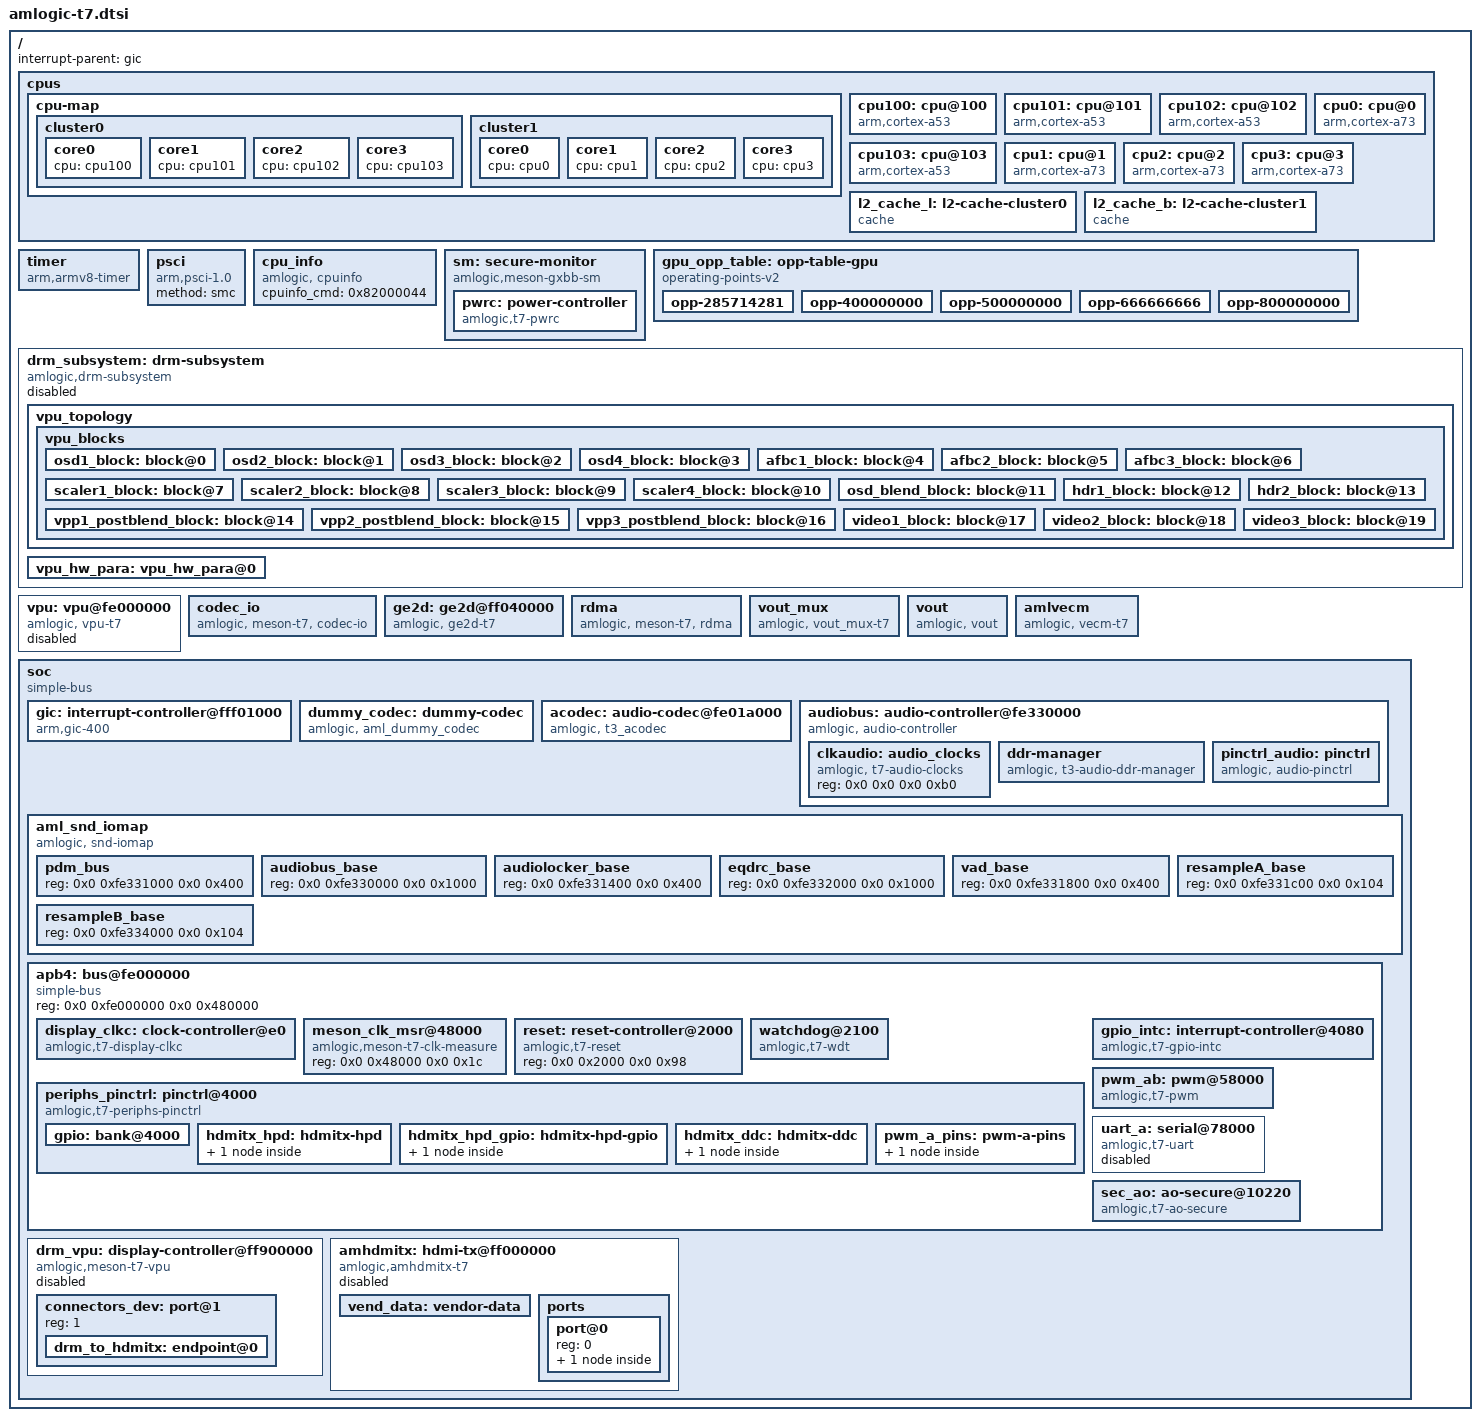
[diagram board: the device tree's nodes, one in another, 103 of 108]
// SPDX-License-Identifier: (GPL-2.0+ OR MIT)
/*
 * Copyright (c) 2019 Amlogic, Inc. All rights reserved.
 */

#include <dt-bindings/interrupt-controller/arm-gic.h>
#include <dt-bindings/clock/amlogic,t7-audio-clk.h>
#include <dt-bindings/clock/amlogic,t7-display-clkc.h>
#include <dt-bindings/display/meson-drm-ids.h>
#include <dt-bindings/power/amlogic,t7-pwrc.h>
#include "amlogic-t7-reset.h"

/ {
	interrupt-parent = <&gic>;
	#address-cells = <2>;
	#size-cells = <2>;

	cpus {
		#address-cells = <0x2>;
		#size-cells = <0x0>;

		cpu-map {
			cluster0 {
				core0 {
					cpu = <&cpu100>;
				};
				core1 {
					cpu = <&cpu101>;
				};
				core2 {
					cpu = <&cpu102>;
				};
				core3 {
					cpu = <&cpu103>;
				};
			};

			cluster1 {
				core0 {
					cpu = <&cpu0>;
				};
				core1 {
					cpu = <&cpu1>;
				};
				core2 {
					cpu = <&cpu2>;
				};
				core3 {
					cpu = <&cpu3>;
				};
			};
		};

		cpu100: cpu@100 {
			device_type = "cpu";
			compatible = "arm,cortex-a53";
			reg = <0x0 0x100>;
			enable-method = "psci";
			d-cache-line-size = <32>;
			d-cache-size = <0x8000>;
			d-cache-sets = <32>;
			i-cache-line-size = <32>;
			i-cache-size = <0x8000>;
			i-cache-sets = <32>;
			next-level-cache = <&l2_cache_l>;
		};

		cpu101: cpu@101 {
			device_type = "cpu";
			compatible = "arm,cortex-a53";
			reg = <0x0 0x101>;
			enable-method = "psci";
			d-cache-line-size = <32>;
			d-cache-size = <0x8000>;
			d-cache-sets = <32>;
			i-cache-line-size = <32>;
			i-cache-size = <0x8000>;
			i-cache-sets = <32>;
			next-level-cache = <&l2_cache_l>;
		};

		cpu102: cpu@102 {
			device_type = "cpu";
			compatible = "arm,cortex-a53";
			reg = <0x0 0x102>;
			enable-method = "psci";
			d-cache-line-size = <32>;
			d-cache-size = <0x8000>;
			d-cache-sets = <32>;
			i-cache-line-size = <32>;
			i-cache-size = <0x8000>;
			i-cache-sets = <32>;
			next-level-cache = <&l2_cache_l>;
		};

		cpu103: cpu@103 {
			device_type = "cpu";
			compatible = "arm,cortex-a53";
			reg = <0x0 0x103>;
			enable-method = "psci";
			d-cache-line-size = <32>;
			d-cache-size = <0x8000>;
			d-cache-sets = <32>;
			i-cache-line-size = <32>;
			i-cache-size = <0x8000>;
			i-cache-sets = <32>;
			next-level-cache = <&l2_cache_l>;
		};

		cpu0: cpu@0 {
			device_type = "cpu";
			compatible = "arm,cortex-a73";
			reg = <0x0 0x0>;
			enable-method = "psci";
			d-cache-line-size = <64>;
			d-cache-size = <0x10000>;
			d-cache-sets = <64>;
			i-cache-line-size = <64>;
			i-cache-size = <0x10000>;
			i-cache-sets = <64>;
			next-level-cache = <&l2_cache_b>;
		};

		cpu1: cpu@1 {
			device_type = "cpu";
			compatible = "arm,cortex-a73";
			reg = <0x0 0x1>;
			enable-method = "psci";
			d-cache-line-size = <64>;
			d-cache-size = <0x10000>;
			d-cache-sets = <64>;
			i-cache-line-size = <64>;
			i-cache-size = <0x10000>;
			i-cache-sets = <64>;
			next-level-cache = <&l2_cache_b>;
		};

		cpu2: cpu@2 {
			device_type = "cpu";
			compatible = "arm,cortex-a73";
			reg = <0x0 0x2>;
			enable-method = "psci";
			d-cache-line-size = <64>;
			d-cache-size = <0x10000>;
			d-cache-sets = <64>;
			i-cache-line-size = <64>;
			i-cache-size = <0x10000>;
			i-cache-sets = <64>;
			next-level-cache = <&l2_cache_b>;
		};

		cpu3: cpu@3 {
			device_type = "cpu";
			compatible = "arm,cortex-a73";
			reg = <0x0 0x3>;
			enable-method = "psci";
			d-cache-line-size = <64>;
			d-cache-size = <0x10000>;
			d-cache-sets = <64>;
			i-cache-line-size = <64>;
			i-cache-size = <0x10000>;
			i-cache-sets = <64>;
			next-level-cache = <&l2_cache_b>;
		};

		l2_cache_l: l2-cache-cluster0 {
			compatible = "cache";
			cache-level = <2>;
			cache-unified;
			cache-size = <0x40000>;  /* L2. 256 KB */
			cache-line-size = <64>;
			cache-sets = <512>;
		};

		l2_cache_b: l2-cache-cluster1 {
			compatible = "cache";
			cache-level = <2>;
			cache-unified;
			cache-size = <0x100000>; /* L2. 1 Mb */
			cache-line-size = <64>;
			cache-sets = <512>;
		};
	};

	timer {
		compatible = "arm,armv8-timer";
		interrupts = <GIC_PPI 13 (GIC_CPU_MASK_SIMPLE(8) | IRQ_TYPE_LEVEL_LOW)>,
			     <GIC_PPI 14 (GIC_CPU_MASK_SIMPLE(8) | IRQ_TYPE_LEVEL_LOW)>,
			     <GIC_PPI 11 (GIC_CPU_MASK_SIMPLE(8) | IRQ_TYPE_LEVEL_LOW)>,
			     <GIC_PPI 10 (GIC_CPU_MASK_SIMPLE(8) | IRQ_TYPE_LEVEL_LOW)>;
	};

	psci {
		compatible = "arm,psci-1.0";
		method = "smc";
	};

	cpu_info {
		compatible = "amlogic, cpuinfo";
		status = "okay";
		cpuinfo_cmd = <0x82000044>;
	};

	sm: secure-monitor {
		compatible = "amlogic,meson-gxbb-sm";

		pwrc: power-controller {
			compatible = "amlogic,t7-pwrc";
			#power-domain-cells = <1>;
		};
	};

	gpu_opp_table: opp-table-gpu {
		compatible = "operating-points-v2";

		opp-285714281 {
			opp-hz = /bits/ 64 <285714281>;
			opp-microvolt = <1150000>;
		};

		opp-400000000 {
			opp-hz = /bits/ 64 <400000000>;
			opp-microvolt = <1150000>;
		};

		opp-500000000 {
			opp-hz = /bits/ 64 <500000000>;
			opp-microvolt = <1150000>;
		};

		opp-666666666 {
			opp-hz = /bits/ 64 <666666666>;
			opp-microvolt = <1150000>;
		};

		opp-800000000 {
			opp-hz = /bits/ 64 <800000000>;
			opp-microvolt = <1150000>;
		};
	};

	drm_subsystem: drm-subsystem {
		compatible = "amlogic,drm-subsystem", "amlogic, drm-subsystem";
		status = "disabled";

		vpu_dma_mask = <1>;
		ports = <&connectors_dev>;
		fbdev_sizes = <1920 1080 1920 2160 32>;
		osd_ver = /bits/ 8 <OSD_V7>;
		vfm_mode = <1>;
		crtc_masks = <7 7 1>;
		crtcmask_of_osd = <0 0 1 2>;
		crtcmask_of_video = <0 1 2>;

		vpu_topology: vpu_topology {
			vpu_blocks {
				osd1_block: block@0 {
					id = /bits/ 8 <OSD1_BLOCK>;
					index = /bits/ 8 <0>;
					type = /bits/ 8 <0>;
					block_name = "osd1_block";
					num_in_links = /bits/ 8 <0x0>;
					num_out_links = /bits/ 8 <0x1>;
					out_links = <0 &afbc1_block>;
				};

				osd2_block: block@1 {
					id = /bits/ 8 <OSD2_BLOCK>;
					index = /bits/ 8 <1>;
					type = /bits/ 8 <0>;
					block_name = "osd2_block";
					num_in_links = /bits/ 8 <0x0>;
					num_out_links = /bits/ 8 <0x1>;
					out_links = <1 &afbc1_block>;
				};

				osd3_block: block@2 {
					id = /bits/ 8 <OSD3_BLOCK>;
					index = /bits/ 8 <2>;
					type = /bits/ 8 <0>;
					block_name = "osd3_block";
					num_in_links = /bits/ 8 <0x0>;
					num_out_links = /bits/ 8 <0x1>;
					out_links = <0 &afbc2_block>;
				};

				osd4_block: block@3 {
					id = /bits/ 8 <OSD4_BLOCK>;
					index = /bits/ 8 <3>;
					type = /bits/ 8 <0>;
					block_name = "osd4_block";
					num_in_links = /bits/ 8 <0x0>;
					num_out_links = /bits/ 8 <0x1>;
					out_links = <0 &afbc3_block>;
				};

				afbc1_block: block@4 {
					id = /bits/ 8 <AFBC1_BLOCK>;
					index = /bits/ 8 <0>;
					type = /bits/ 8 <1>;
					block_name = "afbc1_block";
					num_in_links = /bits/ 8 <0x2>;
					in_links = <0 &osd1_block>,
						   <0 &osd2_block>;
					num_out_links = /bits/ 8 <0x2>;
					out_links = <0 &osd_blend_block>,
						    <0 &scaler2_block>;
				};

				afbc2_block: block@5 {
					id = /bits/ 8 <AFBC2_BLOCK>;
					index = /bits/ 8 <1>;
					type = /bits/ 8 <1>;
					block_name = "afbc2_block";
					num_in_links = /bits/ 8 <0x1>;
					in_links = <0 &osd3_block>;
					num_out_links = /bits/ 8 <0x1>;
					out_links = <0 &scaler3_block>;
				};

				afbc3_block: block@6 {
					id = /bits/ 8 <AFBC3_BLOCK>;
					index = /bits/ 8 <2>;
					type = /bits/ 8 <1>;
					block_name = "afbc3_block";
					num_in_links = /bits/ 8 <0x1>;
					in_links = <0 &osd4_block>;
					num_out_links = /bits/ 8 <0x1>;
					out_links = <0 &scaler4_block>;
				};

				scaler1_block: block@7 {
					id = /bits/ 8 <SCALER1_BLOCK>;
					index = /bits/ 8 <0>;
					type = /bits/ 8 <2>;
					block_name = "scaler1_block";
					num_in_links = /bits/ 8 <0x1>;
					in_links = <0 &hdr1_block>;
					num_out_links = /bits/ 8 <0x1>;
					out_links = <0 &vpp1_postblend_block>;
				};

				scaler2_block: block@8 {
					id = /bits/ 8 <SCALER2_BLOCK>;
					index = /bits/ 8 <1>;
					type = /bits/ 8 <2>;
					block_name = "scaler2_block";
					num_in_links = /bits/ 8 <0x1>;
					in_links = <1 &afbc1_block>;
					num_out_links = /bits/ 8 <0x1>;
					out_links = <1 &osd_blend_block>;
				};

				scaler3_block: block@9 {
					id = /bits/ 8 <SCALER3_BLOCK>;
					index = /bits/ 8 <2>;
					type = /bits/ 8 <2>;
					block_name = "scaler3_block";
					num_in_links = /bits/ 8 <0x1>;
					in_links = <0 &afbc2_block>;
					num_out_links = /bits/ 8 <0x2>;
					out_links = <2 &osd_blend_block>,
						    <0 &hdr2_block>;
				};

				scaler4_block: block@10 {
					id = /bits/ 8 <SCALER4_BLOCK>;
					index = /bits/ 8 <3>;
					type = /bits/ 8 <2>;
					block_name = "scaler4_block";
					num_in_links = /bits/ 8 <0x1>;
					in_links = <0 &afbc3_block>;
					num_out_links = /bits/ 8 <0x2>;
					out_links = <3 &osd_blend_block>,
						    <0 &vpp3_postblend_block>;
				};

				osd_blend_block: block@11 {
					id = /bits/ 8 <OSD_BLEND_BLOCK>;
					block_name = "osd_blend_block";
					type = /bits/ 8 <3>;
					num_in_links = /bits/ 8 <0x4>;
					in_links = <0 &afbc1_block>,
						   <0 &scaler2_block>,
						   <0 &scaler3_block>,
						   <0 &scaler4_block>;
					num_out_links = /bits/ 8 <0x1>;
					out_links = <0 &hdr1_block>;
				};

				hdr1_block: block@12 {
					id = /bits/ 8 <HDR1_BLOCK>;
					index = /bits/ 8 <0>;
					block_name = "hdr1_block";
					type = /bits/ 8 <4>;
					num_in_links = /bits/ 8 <0x1>;
					in_links = <0 &osd_blend_block>;
					num_out_links = /bits/ 8 <0x1>;
					out_links = <0 &scaler1_block>;
				};

				hdr2_block: block@13 {
					id = /bits/ 8 <HDR2_BLOCK>;
					index = /bits/ 8 <1>;
					block_name = "hdr2_block";
					type = /bits/ 8 <4>;
					num_in_links = /bits/ 8 <0x1>;
					in_links = <1 &osd_blend_block>;
					num_out_links = /bits/ 8 <0x1>;
					out_links = <0 &vpp2_postblend_block>;
				};

				vpp1_postblend_block: block@14 {
					id = /bits/ 8 <VPP1_POSTBLEND_BLOCK>;
					index = /bits/ 8 <0>;
					block_name = "vpp1_postblend_block";
					type = /bits/ 8 <6>;
					num_in_links = /bits/ 8 <0x1>;
					in_links = <0 &scaler1_block>;
					num_out_links = <0x0>;
				};

				vpp2_postblend_block: block@15 {
					id = /bits/ 8 <VPP2_POSTBLEND_BLOCK>;
					index = /bits/ 8 <1>;
					block_name = "vpp2_postblend_block";
					type = /bits/ 8 <6>;
					num_in_links = /bits/ 8 <0x1>;
					in_links = <1 &hdr2_block>;
					num_out_links = <0x0>;
				};

				vpp3_postblend_block: block@16 {
					id = /bits/ 8 <VPP3_POSTBLEND_BLOCK>;
					index = /bits/ 8 <2>;
					block_name = "vpp3_postblend_block";
					type = /bits/ 8 <6>;
					num_in_links = /bits/ 8 <0x1>;
					in_links = <0 &scaler4_block>;
					num_out_links = <0x0>;
				};

				video1_block: block@17 {
					id = /bits/ 8 <VIDEO1_BLOCK>;
					index = /bits/ 8 <0>;
					type = /bits/ 8 <7>;
					block_name = "video1_block";
					num_in_links = /bits/ 8 <0x0>;
					num_out_links = /bits/ 8 <0x0>;
				};

				video2_block: block@18 {
					id = /bits/ 8 <VIDEO2_BLOCK>;
					index = /bits/ 8 <1>;
					type = /bits/ 8 <7>;
					block_name = "video2_block";
					num_in_links = /bits/ 8 <0x0>;
					num_out_links = /bits/ 8 <0x0>;
				};

				video3_block: block@19 {
					id = /bits/ 8 <VIDEO3_BLOCK>;
					index = /bits/ 8 <2>;
					type = /bits/ 8 <7>;
					block_name = "video3_block";
					num_in_links = /bits/ 8 <0x0>;
					num_out_links = /bits/ 8 <0x0>;
				};
			};
		};

		vpu_hw_para: vpu_hw_para@0 {
			osd_ver = /bits/ 8 <OSD_V7>;
			afbc_type = /bits/ 8 <0x2>;
			has_deband = /bits/ 8 <0x1>;
			has_lut = /bits/ 8 <0x1>;
			has_rdma = /bits/ 8 <0x1>;
			osd_fifo_len = /bits/ 8 <64>;
			vpp_fifo_len = /bits/ 32 <0xfff>;
		};
	};

	vpu: vpu@fe000000 {
		compatible = "amlogic, vpu-t7";
		status = "disabled";
		reg = <0x0 0xfe000000 0x0 0x100>,
		      <0x0 0xfe00c000 0x0 0x70>,
		      <0x0 0xff000000 0x0 0xf000>;
		clocks = <&display_clkc CLKID_T7_DISPLAY_VAPB>,
			 <&clkc_periphs CLKID_SYS_VPU_INTR>,
			 <&display_clkc CLKID_T7_DISPLAY_VPU_0>,
			 <&display_clkc CLKID_T7_DISPLAY_VPU_1>,
			 <&display_clkc CLKID_T7_DISPLAY_VPU>;
		clock-names = "vapb_clk", "vpu_intr_gate",
			      "vpu_clk0", "vpu_clk1", "vpu_clk";
		clk_level = <8>;
	};

	codec_io: codec_io {
		compatible = "amlogic, meson-t7, codec-io";
		status = "okay";
		#address-cells = <2>;
		#size-cells = <2>;
		ranges;
		/* Positional resources used by the vendor codec_io bus enum. */
		reg = <0x0 0xfe002000 0x0 0x2000>,
		      <0x0 0xfe320000 0x0 0x10000>,
		      <0x0 0x0 0x0 0x0>,
		      <0x0 0x0 0x0 0x0>,
		      <0x0 0xff000000 0x0 0x40000>,
		      <0x0 0xfe036000 0x0 0x2000>,
		      <0x0 0x0 0x0 0x0>;
		reg-names = "cbus",
			    "dosbus",
			    "hiubus",
			    "aobus",
			    "vcbus",
			    "dmcbus",
			    "efusebus";
	};

	ge2d: ge2d@ff040000 {
		compatible = "amlogic, ge2d-t7";
		status = "okay";
		interrupts = <GIC_SPI 217 IRQ_TYPE_EDGE_RISING>;
		interrupt-names = "ge2d";
		clocks = <&display_clkc CLKID_T7_DISPLAY_VAPB>,
			 <&clkc_periphs CLKID_SYS_G2D>,
			 <&display_clkc CLKID_T7_DISPLAY_GE2D>;
		clock-names = "clk_vapb_0",
			      "clk_ge2d",
			      "clk_ge2d_gate";
		reg = <0x0 0xff040000 0x0 0x100>;
		power-domains = <&pwrc PWRC_T7_GE2D_ID>;
	};

	rdma {
		compatible = "amlogic, meson-t7, rdma";
		status = "okay";
		interrupts = <GIC_SPI 215 IRQ_TYPE_EDGE_RISING>;
		interrupt-names = "rdma";
		reset-names = "rdma";
		resets = <&reset RESET_RDMA>;
		rdma_table_page_count = <16>;
	};

	vout_mux: vout_mux {
		compatible = "amlogic, vout_mux-t7";
		status = "okay";
	};

	vout: vout {
		compatible = "amlogic, vout";
		status = "okay";
	};

	amlvecm: amlvecm {
		compatible = "amlogic, vecm-t7", "amlogic, vecm";
		dev_name = "aml_vecm";
		clocks = <&display_clkc CLKID_T7_DISPLAY_VID_LOCK>;
		clock-names = "cts_vid_lock_clk";
	};

	soc {
		compatible = "simple-bus";
		#address-cells = <2>;
		#size-cells = <2>;
		ranges;

		gic: interrupt-controller@fff01000 {
			compatible = "arm,gic-400";
			#interrupt-cells = <3>;
			#address-cells = <0>;
			interrupt-controller;
			reg = <0x0 0xfff01000 0 0x1000>,
			      <0x0 0xfff02000 0 0x2000>,
			      <0x0 0xfff04000 0 0x2000>,
			      <0x0 0xfff06000 0 0x2000>;
			interrupts = <GIC_PPI 9 (GIC_CPU_MASK_SIMPLE(8) | IRQ_TYPE_LEVEL_HIGH)>;
		};

		dummy_codec: dummy-codec {
			compatible = "amlogic, aml_dummy_codec";
			#sound-dai-cells = <0>;
			status = "okay";
		};

		acodec: audio-codec@fe01a000 {
			compatible = "amlogic, t3_acodec";
			reg = <0x0 0xfe01a000 0x0 0x1c>;
			clocks = <&clkc_periphs CLKID_SYS_ACODEC>;
			clock-names = "acodec_clk";
			resets = <&reset RESET_ACODEC>;
			reset-names = "acodec";
			#sound-dai-cells = <0>;
			tdmout_index = <1>;
			tdmin_index = <1>;
			dat0_ch_sel = <1>;
			lane_offset = <8>;
			amlogic,skip-reset-startup;
			status = "okay";
		};

		audiobus: audio-controller@fe330000 {
			compatible = "amlogic, audio-controller", "simple-bus";
			reg = <0x0 0xfe330000 0x0 0x3000>;
			clocks = <&clkc_periphs CLKID_SYS_AUDIO>;
			clock-names = "pclk";
			power-domains = <&pwrc PWRC_T7_AUDIO_ID>;
			#address-cells = <2>;
			#size-cells = <2>;
			ranges = <0x0 0x0 0x0 0xfe330000 0x0 0x3000>;
			chip_id = <0x36>;
			status = "okay";

			clkaudio: audio_clocks {
				compatible = "amlogic, t7-audio-clocks";
				#clock-cells = <1>;
				reg = <0x0 0x0 0x0 0xb0>;
				status = "okay";
			};

			ddr-manager {
				compatible = "amlogic, t3-audio-ddr-manager";
				interrupts = <GIC_SPI 32 IRQ_TYPE_EDGE_RISING>,
					     <GIC_SPI 33 IRQ_TYPE_EDGE_RISING>,
					     <GIC_SPI 34 IRQ_TYPE_EDGE_RISING>,
					     <GIC_SPI 45 IRQ_TYPE_EDGE_RISING>,
					     <GIC_SPI 40 IRQ_TYPE_EDGE_RISING>,
					     <GIC_SPI 36 IRQ_TYPE_EDGE_RISING>,
					     <GIC_SPI 37 IRQ_TYPE_EDGE_RISING>,
					     <GIC_SPI 38 IRQ_TYPE_EDGE_RISING>,
					     <GIC_SPI 46 IRQ_TYPE_EDGE_RISING>,
					     <GIC_SPI 47 IRQ_TYPE_EDGE_RISING>;
				interrupt-names = "toddr_a", "toddr_b", "toddr_c",
						  "toddr_d", "toddr_e",
						  "frddr_a", "frddr_b", "frddr_c",
						  "frddr_d", "frddr_e";
				status = "okay";
			};

			pinctrl_audio: pinctrl {
				compatible = "amlogic, audio-pinctrl";
				status = "okay";
			};
		};

		aml_snd_iomap {
			compatible = "amlogic, snd-iomap";
			status = "okay";
			#address-cells = <2>;
			#size-cells = <2>;
			ranges;

			pdm_bus {
				reg = <0x0 0xfe331000 0x0 0x400>;
			};

			audiobus_base {
				reg = <0x0 0xfe330000 0x0 0x1000>;
			};

			audiolocker_base {
				reg = <0x0 0xfe331400 0x0 0x400>;
			};

			eqdrc_base {
				reg = <0x0 0xfe332000 0x0 0x1000>;
			};

			vad_base {
				reg = <0x0 0xfe331800 0x0 0x400>;
			};

			resampleA_base {
				reg = <0x0 0xfe331c00 0x0 0x104>;
			};

			resampleB_base {
				reg = <0x0 0xfe334000 0x0 0x104>;
			};
		};

		apb4: bus@fe000000 {
			compatible = "simple-bus";
			reg = <0x0 0xfe000000 0x0 0x480000>;
			#address-cells = <2>;
			#size-cells = <2>;
			ranges = <0x0 0x0 0x0 0xfe000000 0x0 0x480000>;

			display_clkc: clock-controller@e0 {
				compatible = "amlogic,t7-display-clkc";
				reg = <0x0 0x00e0 0x0 0x44>,
				      <0x0 0x0140 0x0 0x10>;
				#clock-cells = <1>;
				clocks = <&xtal>,
					 <&fdiv2p5>,
					 <&fdiv3>,
					 <&fdiv4>,
					 <&fdiv5>,
					 <&fdiv7>;
				clock-names = "xtal",
					      "fdiv2p5",
					      "fdiv3",
					      "fdiv4",
					      "fdiv5",
					      "fdiv7";
			};

			meson_clk_msr@48000 {
				compatible = "amlogic,meson-t7-clk-measure";
				reg = <0x0 0x48000 0x0 0x1c>;
			};

			reset: reset-controller@2000 {
				compatible = "amlogic,t7-reset";
				reg = <0x0 0x2000 0x0 0x98>;
				#reset-cells = <1>;
			};

			watchdog@2100 {
				compatible = "amlogic,t7-wdt";
				reg = <0x0 0x2100 0x0 0x10>;
				clocks = <&xtal>;
			};

			periphs_pinctrl: pinctrl@4000 {
				compatible = "amlogic,t7-periphs-pinctrl";
				#address-cells = <2>;
				#size-cells = <2>;
				ranges;

				gpio: bank@4000 {
					reg = <0x0 0x4000 0x0 0x0064>,
					      <0x0 0x40c0 0x0 0x0220>;
					reg-names = "mux", "gpio";
					gpio-controller;
					#gpio-cells = <2>;
					gpio-ranges = <&periphs_pinctrl 0 0 157>;
				};

				hdmitx_hpd: hdmitx-hpd {
					mux {
						groups = "hdmitx_hpd_in";
						function = "hdmitx";
						bias-disable;
					};
				};

				hdmitx_hpd_gpio: hdmitx-hpd-gpio {
					mux {
						groups = "GPIOW_15";
						function = "gpio_periphs";
						bias-disable;
					};
				};

				hdmitx_ddc: hdmitx-ddc {
					mux {
						groups = "hdmitx_sda_w13", "hdmitx_sck_w14";
						function = "hdmitx";
						bias-disable;
						drive-strength-microamp = <3000>;
					};
				};

				pwm_a_pins: pwm-a-pins {
					mux {
						groups = "pwm_a";
						function = "pwm_a";
						bias-disable;
					};
				};
			};

			gpio_intc: interrupt-controller@4080 {
				compatible = "amlogic,t7-gpio-intc",
					     "amlogic,meson-gpio-intc";
				reg = <0x0 0x4080 0x0 0x20>;
				interrupt-controller;
				#interrupt-cells = <2>;
				amlogic,channel-interrupts =
					<10 11 12 13 14 15 16 17 18 19 20 21>;
			};

			pwm_ab: pwm@58000 {
				compatible = "amlogic,t7-pwm", "amlogic,meson-s4-pwm";
				reg = <0x0 0x58000 0x0 0x24>;
				clocks = <&clkc_periphs CLKID_PWM_A>,
					 <&clkc_periphs CLKID_PWM_B>;
				#pwm-cells = <3>;
				status = "okay";
			};

			uart_a: serial@78000 {
				compatible = "amlogic,t7-uart", "amlogic,meson-s4-uart";
				reg = <0x0 0x78000 0x0 0x18>;
				interrupts = <GIC_SPI 168 IRQ_TYPE_EDGE_RISING>;
				status = "disabled";
			};

			sec_ao: ao-secure@10220 {
				compatible = "amlogic,t7-ao-secure",
					     "amlogic,meson-gx-ao-secure",
					     "syscon";
				reg = <0x0 0x10220 0x0 0x140>;
				amlogic,has-chip-id;
			};
		};

		drm_vpu: display-controller@ff900000 {
			compatible = "amlogic,meson-t7-vpu", "amlogic, meson-t7-vpu";
			status = "disabled";
			osd_ver = /bits/ 8 <OSD_V7>;
			osd_axi_sel = <0>;
			power-domains = <&pwrc PWRC_T7_VPU_HDMI_ID>;
			clocks = <&display_clkc CLKID_T7_DISPLAY_VAPB>,
				 <&clkc_periphs CLKID_SYS_VPU_INTR>,
				 <&display_clkc CLKID_T7_DISPLAY_VPU_0>,
				 <&display_clkc CLKID_T7_DISPLAY_VPU_1>,
				 <&display_clkc CLKID_T7_DISPLAY_VPU>;
			clock-names = "vapb_clk", "vpu_intr_gate",
				      "vpu_clk0", "vpu_clk1", "vpu_clk";
			resets = <&reset RESET_VIU>,
				 <&reset RESET_VENC>;
			reset-names = "viu", "venc";
			reg = <0x0 0xff900000 0x0 0x40000>,
			      <0x0 0xff63c000 0x0 0x2000>,
			      <0x0 0xff638000 0x0 0x2000>;
			reg-names = "base", "hhi", "dmc";
			interrupts = <GIC_SPI 197 IRQ_TYPE_EDGE_RISING>,
				     <GIC_SPI 194 IRQ_TYPE_EDGE_RISING>,
				     <GIC_SPI 82 IRQ_TYPE_EDGE_RISING>;
			interrupt-names = "drm-viu-vsync", "drm-viu2-vsync",
					  "drm-viu3-vsync";
			dma-coherent;

			#address-cells = <1>;
			#size-cells = <0>;

			connectors_dev: port@1 {
				reg = <1>;
				#address-cells = <1>;
				#size-cells = <0>;

				drm_to_hdmitx: endpoint@0 {
					reg = <0>;
					remote-endpoint = <&hdmitx_to_drm>;
				};
			};
		};

		amhdmitx: hdmi-tx@ff000000 {
			compatible = "amlogic,amhdmitx-t7", "amlogic, amhdmitx-t7";
			dev_name = "amhdmitx";
			status = "disabled";
			power-domains = <&pwrc PWRC_T7_VI_CLK2_ID>;
			clocks = <&clkc_periphs CLKID_SYS_HDMITX_APB>,
				 <&display_clkc CLKID_T7_DISPLAY_HDMITX_SYS>,
				 <&display_clkc CLKID_T7_DISPLAY_HDMITX_PRIF>,
				 <&display_clkc CLKID_T7_DISPLAY_HDMITX_200M>,
				 <&display_clkc CLKID_T7_DISPLAY_VAPB>,
				 <&display_clkc CLKID_T7_DISPLAY_VPU>;
			clock-names = "pclk", "hdmitx_sys", "hdmitx_prif",
				      "hdmitx_200m", "hdmi_vapb_clk", "hdmi_vpu_clk";
			resets = <&reset RESET_HDMITX>,
				 <&reset RESET_HDMITXPHY>;
			reset-names = "hdmitx", "hdmitxphy";
			pinctrl-names = "hdmitx_hpd", "hdmitx_ddc";
			pinctrl-0 = <&hdmitx_hpd>;
			pinctrl-1 = <&hdmitx_ddc>;
			hdmitx-gpios-hpd = <&gpio GPIOW_15 GPIO_ACTIVE_HIGH>;
			hdmitx-gpios-scl = <&gpio GPIOW_14 GPIO_ACTIVE_HIGH>;
			hdmitx-gpios-sda = <&gpio GPIOW_13 GPIO_ACTIVE_HIGH>;
			enc_idx = <0>;
			vend-data = <&vend_data>;
			interrupts = <GIC_SPI 204 IRQ_TYPE_LEVEL_HIGH>,
				     <GIC_SPI 197 IRQ_TYPE_EDGE_RISING>;
			interrupt-names = "hdmitx_hpd", "vrr_vsync";
			reg = <0x0 0xff000000 0x0 0x40000>,
			      <0x0 0xfe380000 0x0 0x10000>,
			      <0x0 0xfe300000 0x0 0x10000>,
			      <0x0 0xfe010000 0x0 0x2000>,
			      <0x0 0xfe00c000 0x0 0x2000>,
			      <0x0 0xfe008000 0x0 0x2000>,
			      <0x0 0xfe002000 0x0 0x2000>,
			      <0x0 0xfe000000 0x0 0x2000>,
				      <0x0 0xfe004000 0x0 0x2000>;
			reg-names = "vpu", "hdmitx_cor", "hdmitx_top", "sysctrl",
				    "pwrctrl", "anactrl", "resetctrl", "clkctrl",
				    "padctrl";

			vend_data: vendor-data {
				vendor_name = "Amlogic";
				product_desc = "T7";
				vendor_id = <0x000000>;
			};

			ports {
				#address-cells = <1>;
				#size-cells = <0>;

				port@0 {
					reg = <0>;
					#address-cells = <1>;
					#size-cells = <0>;

					hdmitx_to_drm: endpoint@0 {
						reg = <0>;
						remote-endpoint = <&drm_to_hdmitx>;
					};
				};
			};
		};

	};
};
